AUTOSAR XML (schema 4-0-3)
package /ComponentTypes
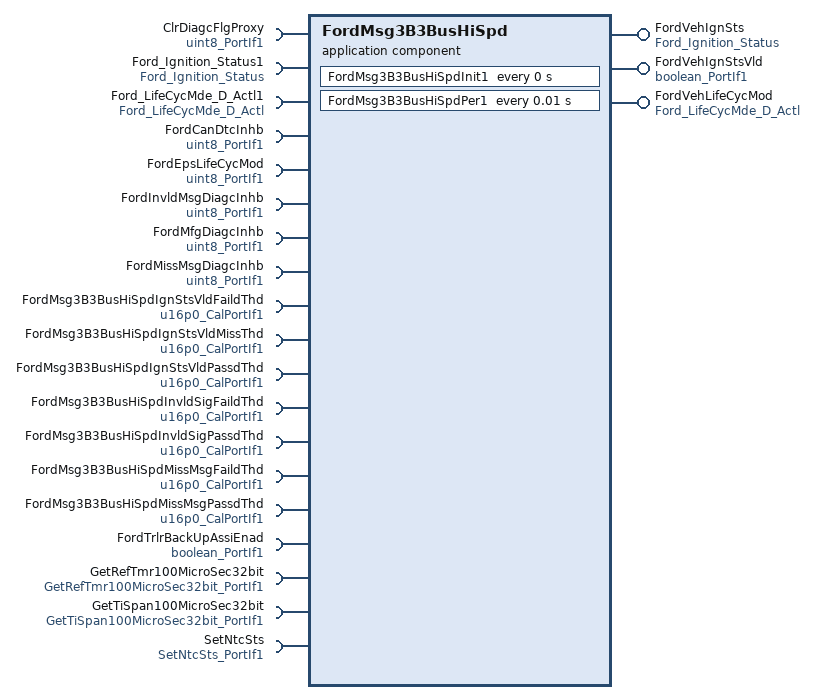
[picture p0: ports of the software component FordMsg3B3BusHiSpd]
  application sw component type FordMsg3B3BusHiSpd
    provide port FordVehIgnSts: nonqueued-sender-com-spec{data-element=Ford_Ignition_Status, init-value=0}, provided-interface=Ford_Ignition_Status
    provide port FordVehIgnStsVld: nonqueued-sender-com-spec{data-element=Logl, init-value=0}, provided-interface=boolean_PortIf1
    provide port FordVehLifeCycMod: nonqueued-sender-com-spec{data-element=Ford_LifeCycMde_D_Actl, init-value=0}, provided-interface=Ford_LifeCycMde_D_Actl
    19 x require port:
      ClrDiagcFlgProxy: nonqueued-receiver-com-spec{data-element=Val, filter=data-filter-type=ALWAYS, init-value=0}, required-interface=uint8_PortIf1
      Ford_Ignition_Status1: nonqueued-receiver-com-spec{data-element=Ford_Ignition_Status, filter=data-filter-type=ALWAYS, init-value=0}, required-interface=Ford_Ignition_Status
      Ford_LifeCycMde_D_Actl1: nonqueued-receiver-com-spec{data-element=Ford_LifeCycMde_D_Actl, filter=data-filter-type=ALWAYS, init-value=0}, required-interface=Ford_LifeCycMde_D_Actl
      FordCanDtcInhb: nonqueued-receiver-com-spec{data-element=Val, filter=data-filter-type=ALWAYS, init-value=1}, required-interface=uint8_PortIf1
      FordEpsLifeCycMod: nonqueued-receiver-com-spec{data-element=Val, filter=data-filter-type=ALWAYS, init-value=0}, required-interface=uint8_PortIf1
      FordInvldMsgDiagcInhb: nonqueued-receiver-com-spec{data-element=Val, filter=data-filter-type=ALWAYS, init-value=0}, required-interface=uint8_PortIf1
      FordMfgDiagcInhb: nonqueued-receiver-com-spec{data-element=Val, filter=data-filter-type=ALWAYS, init-value=0}, required-interface=uint8_PortIf1
      FordMissMsgDiagcInhb: nonqueued-receiver-com-spec{data-element=Val, filter=data-filter-type=ALWAYS, init-value=0}, required-interface=uint8_PortIf1
      FordMsg3B3BusHiSpdIgnStsVldFaildThd: parameter-require-com-spec{init-value=0, parameter=Val}, required-interface=u16p0_CalPortIf1
      FordMsg3B3BusHiSpdIgnStsVldMissThd: parameter-require-com-spec{init-value=100, parameter=Val}, required-interface=u16p0_CalPortIf1
      FordMsg3B3BusHiSpdIgnStsVldPassdThd: parameter-require-com-spec{init-value=0, parameter=Val}, required-interface=u16p0_CalPortIf1
      FordMsg3B3BusHiSpdInvldSigFaildThd: parameter-require-com-spec{init-value=0, parameter=Val}, required-interface=u16p0_CalPortIf1
      FordMsg3B3BusHiSpdInvldSigPassdThd: parameter-require-com-spec{init-value=0, parameter=Val}, required-interface=u16p0_CalPortIf1
      FordMsg3B3BusHiSpdMissMsgFaildThd: parameter-require-com-spec{init-value=100, parameter=Val}, required-interface=u16p0_CalPortIf1
      FordMsg3B3BusHiSpdMissMsgPassdThd: parameter-require-com-spec{init-value=0, parameter=Val}, required-interface=u16p0_CalPortIf1
      FordTrlrBackUpAssiEnad: nonqueued-receiver-com-spec{data-element=Logl, filter=data-filter-type=ALWAYS, init-value=0}, required-interface=boolean_PortIf1
      GetRefTmr100MicroSec32bit: client-com-spec=Oper, required-interface=GetRefTmr100MicroSec32bit_PortIf1
      GetTiSpan100MicroSec32bit: client-com-spec=Oper, required-interface=GetTiSpan100MicroSec32bit_PortIf1
      SetNtcSts: client-com-spec=Oper, required-interface=SetNtcSts_PortIf1
    behavior FordMsg3B3BusHiSpd_InternalBehavior: port-api-option{enable-take-address=false, indirect-api=false, port=FordCanDtcInhb}
      ar-typed-per-instance-memorys:
        14 x data, all with sw-calibration-access=READ-ONLY:
          ClrDiagcFlgProxyPrev: type=uint8
          FirstTranVldFlg: type=boolean
          FordVehIgnStsInvldSigFaildRefTi: type=uint32
          FordVehIgnStsInvldSigPassdRefTi: type=uint32
          FordVehIgnStsPrev: type=Ford_Ignition_Status
          FordVehIgnStsVldPrev: type=boolean
          FordVehLifeCycModPrev: type=Ford_LifeCycMde_D_Actl
          FordVehMsg3B3Miss: type=boolean
          FordVehMsg3B3Rxd: type=boolean
          IgnStsVldFaildRefTi: type=uint32
          IgnStsVldMissRefTi: type=uint32
          IgnStsVldPassdRefTi: type=uint32
          MissMsgFaildRefTi: type=uint32
          MissMsgPassdRefTi: type=uint32
      timing event FordMsg3B3BusHiSpd_InitEvent: start-on-event=FordMsg3B3BusHiSpdInit1, period=0
      timing event TMT_FordMsg3B3BusHiSpdPer1: start-on-event=FordMsg3B3BusHiSpdPer1, period=0.01
      runnable FordMsg3B3BusHiSpdInit1
        sync call SC_GetRefTmr100MicroSec32bit_Oper: operation=GetRefTmr100MicroSec32bit.Oper, timeout=0
      runnable FordMsg3B3BusHiSpdPer1
        data-receive-point-by-arguments:
          9 x access:
            REC_ClrDiagcFlgProxy_Val: accessed-variable=ClrDiagcFlgProxy.Val
            REC_Ford_Ignition_Status1_Ford_Ignition_Status: accessed-variable=Ford_Ignition_Status1.Ford_Ignition_Status
            REC_Ford_LifeCycMde_D_Actl1_Ford_LifeCycMde_D_Actl: accessed-variable=Ford_LifeCycMde_D_Actl1.Ford_LifeCycMde_D_Actl
            REC_FordCanDtcInhb_Val: accessed-variable=FordCanDtcInhb.Val
            REC_FordEpsLifeCycMod_Val: accessed-variable=FordEpsLifeCycMod.Val
            REC_FordInvldMsgDiagcInhb_Val: accessed-variable=FordInvldMsgDiagcInhb.Val
            REC_FordMfgDiagcInhb_Val: accessed-variable=FordMfgDiagcInhb.Val
            REC_FordMissMsgDiagcInhb_Val: accessed-variable=FordMissMsgDiagcInhb.Val
            REC_FordTrlrBackUpAssiEnad_Logl: accessed-variable=FordTrlrBackUpAssiEnad.Logl
        data-send-points:
          access SEND_FordVehIgnSts_Ford_Ignition_Status: accessed-variable=FordVehIgnSts.Ford_Ignition_Status
          access SEND_FordVehIgnStsVld_Logl: accessed-variable=FordVehIgnStsVld.Logl
          access SEND_FordVehLifeCycMod_Ford_LifeCycMde_D_Actl: accessed-variable=FordVehLifeCycMod.Ford_LifeCycMde_D_Actl
        sync call SC_GetRefTmr100MicroSec32bit_Oper: operation=GetRefTmr100MicroSec32bit.Oper, timeout=0
        sync call SC_GetTiSpan100MicroSec32bit_Oper: operation=GetTiSpan100MicroSec32bit.Oper, timeout=0
        sync call SC_SetNtcSts_Oper: operation=SetNtcSts.Oper, timeout=0
  swc implementation FordMsg3B3BusHiSpd_Implementation: behavior=FordMsg3B3BusHiSpd_InternalBehavior
    code-descriptors:
      code Default: artifact-descriptors=autosar-engineering-object={short-label=Default, category=SWSRC}
